# PIC18F46Q24 register map
Vendor: Microchip
Registers are 8-bit, read-write, reset 0x0 unless marked. A register's access mark holds for its fields unless they carry their own. Addresses are absolute, and some are shared; only a register's first bit layout is shown; [hi:lo] are bit positions; {n}, {i} and the like mark numbered series; 'fields as' and 'values as' point back to an identical list.

## tmr
0x312 TMR1L
0x313 TMR1H
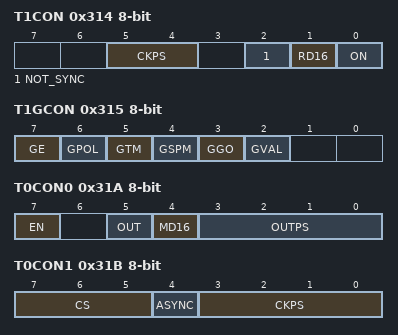
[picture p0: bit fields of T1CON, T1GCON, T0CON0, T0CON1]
0x314 T1CON
  [5:4] CKPS, [2] NOT_SYNC, [1] RD16, [0] ON
0x315 T1GCON reset not defined — (power-on value 00000x--)
  [7] GE, [6] GPOL, [5] GTM, [4] GSPM, [3] GGO, [2] GVAL ro
0x316 T1GATE
  [4:0] GSS
0x317 T1CLK
  [4:0] CS
0x318 TMR0L
0x319 TMR0H reset 0xFF
0x31A T0CON0
  [7] EN, [5] OUT ro, [4] MD16, [3:0] OUTPS
0x31B T0CON1
  [7:5] CS, [4] ASYNC, [3:0] CKPS
0x31D T2TMR — 8-bit period timer
  [7:0] TMR2
0x31E T2PR reset 0xFF
  [7:0] PR2
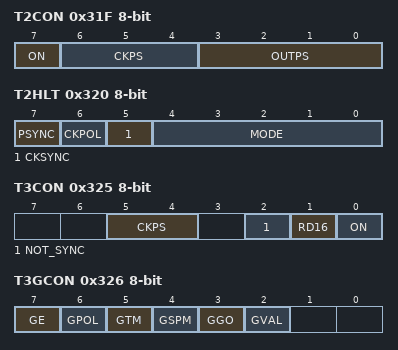
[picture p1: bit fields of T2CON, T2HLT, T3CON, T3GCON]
0x31F T2CON
  [7] ON, [6:4] CKPS, [3:0] OUTPS
0x320 T2HLT
  [7] PSYNC, [6] CKPOL, [5] CKSYNC, [4:0] MODE
0x321 T2CLKCON
  [4:0] CS
0x322 T2RST
  [4:0] RSEL
0x323 TMR3L
0x324 TMR3H
0x325 T3CON
  [5:4] CKPS, [2] NOT_SYNC, [1] RD16, [0] ON
0x326 T3GCON reset not defined — (power-on value 00000x--)
  [7] GE, [6] GPOL, [5] GTM, [4] GSPM, [3] GGO, [2] GVAL ro
0x327 T3GATE
  [4:0] GSS
0x328 T3CLK
  [4:0] CS
0x32A T4TMR — 8-bit period timer
  [7:0] TMR4
0x32B T4PR reset 0xFF
  [7:0] PR4
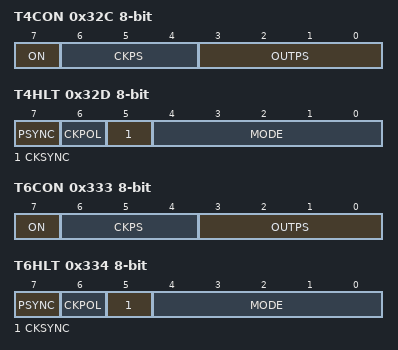
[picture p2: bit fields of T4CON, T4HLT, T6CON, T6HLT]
0x32C T4CON
  [7] ON, [6:4] CKPS, [3:0] OUTPS
0x32D T4HLT
  [7] PSYNC, [6] CKPOL, [5] CKSYNC, [4:0] MODE
0x32E T4CLKCON
  [4:0] CS
0x32F T4RST
  [4:0] RSEL
0x331 T6TMR — 8-bit period timer
  [7:0] TMR6
0x332 T6PR reset 0xFF
  [7:0] PR6
0x333 T6CON
  [7] ON, [6:4] CKPS, [3:0] OUTPS
0x334 T6HLT
  [7] PSYNC, [6] CKPOL, [5] CKSYNC, [4:0] MODE
0x335 T6CLKCON
  [4:0] CS
0x336 T6RST
  [4:0] RSEL
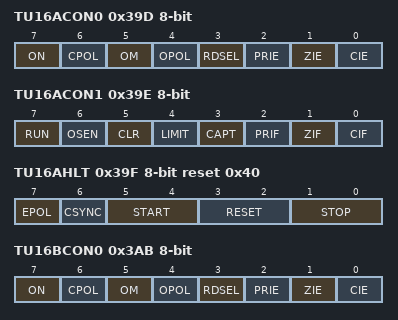
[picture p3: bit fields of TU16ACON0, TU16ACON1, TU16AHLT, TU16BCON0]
0x39D TU16ACON0
  [7] ON, [6] CPOL, [5] OM, [4] OPOL, [3] RDSEL, [2] PRIE, [1] ZIE, [0] CIE
0x39E TU16ACON1
  [7] RUN ro, [6] OSEN, [5] CLR, [4] LIMIT, [3] CAPT, [2] PRIF, [1] ZIF, [0] CIF
0x39F TU16AHLT reset 0x40
  [7] EPOL, [6] CSYNC, [5:4] START, [3:2] RESET, [1:0] STOP
0x3A0 TU16APS
  [7:0] PS
0x3A5 TU16APRL reset 0xFF
  [7:0] PRL
0x3A6 TU16APRH reset 0xFF
  [7:0] PRH
0x3A8 TU16APRT reset 0xFF
  [7:0] PRT
0x3A9 TU16ACLK
  [4:0] CLK
0x3AA TU16AERS
  [5:0] ERS
0x3AB TU16BCON0
  fields as TU16ACON0
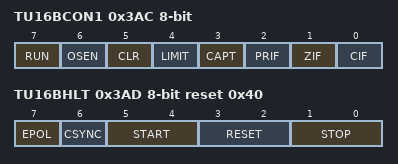
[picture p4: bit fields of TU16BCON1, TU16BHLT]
0x3AC TU16BCON1
  fields as TU16ACON1
0x3AD TU16BHLT reset 0x40
  [7] EPOL, [6] CSYNC, [5:4] START, [3:2] RESET, [1:0] STOP
0x3AE TU16BPS
  [7:0] PS
0x3B3 TU16BPRL reset 0xFF
  [7:0] PRL
0x3B4 TU16BPRH reset 0xFF
  [7:0] PRH
0x3B6 TU16BPRT reset 0xFF
  [7:0] PRT
0x3B7 TU16BCLK
  [4:0] CLK
0x3B8 TU16BERS
  [5:0] ERS

## ccp
0x340 CCPR1L reset not defined — (power-on value xxxxxxxx)
  [7:0] RL
0x341 CCPR1H reset not defined — (power-on value xxxxxxxx)
  [7:0] RH
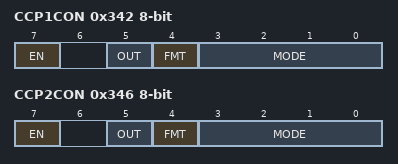
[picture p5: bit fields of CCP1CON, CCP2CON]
0x342 CCP1CON
  [7] EN, [5] OUT ro, [4] FMT, [3:0] MODE
0x343 CCP1CAP
  [3:0] CTS
0x344 CCPR2L reset not defined — (power-on value xxxxxxxx)
  [7:0] RL
0x345 CCPR2H reset not defined — (power-on value xxxxxxxx)
  [7:0] RH
0x346 CCP2CON
  [7] EN, [5] OUT ro, [4] FMT, [3:0] MODE
0x347 CCP2CAP
  [3:0] CTS

## math_progcrc
0x34E CRCDATAL
  [7:0] DATA
0x34F CRCDATAH
  [7:0] DATA
0x350 CRCDATAU
  [7:0] DATA
0x351 CRCDATAT
  [7:0] DATA
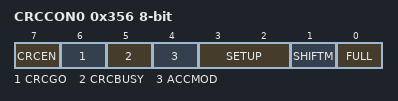
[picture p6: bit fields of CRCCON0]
0x356 CRCCON0
  [7] CRCEN, [6] CRCGO, [5] CRCBUSY ro, [4] ACCMOD, [3:2] SETUP, [1] SHIFTM, [0] FULL ro
0x357 CRCCON1
  [4:0] PLEN
0x358 CRCCON2
  [4:0] DLEN

## nvm_scan
0x35A SCANLADRL
  [7:0] LADR
0x35B SCANLADRH
  [7:0] LADR
0x35C SCANLADRU
  [5:0] LADR
0x35D SCANHADRL reset 0xFF
  [7:0] HADR
0x35E SCANHADRH reset 0xFF
  [7:0] HADR
0x35F SCANHADRU reset 0x3F
  [5:0] HADR
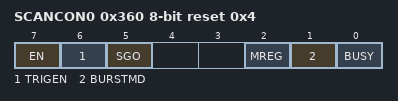
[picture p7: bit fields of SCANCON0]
0x360 SCANCON0 reset 0x4
  [7] EN, [6] TRIGEN, [5] SGO, [2] MREG, [1] BURSTMD, [0] BUSY
0x361 SCANTRIG
  [4:0] TSEL

## wg_ecwg
0x3BC CWG1CLK
  [0] CS
0x3BD CWG1ISM
  [4:0] ISM
0x3BE CWG1DBR
  [5:0] DBR
0x3BF CWG1DBF
  [5:0] DBF
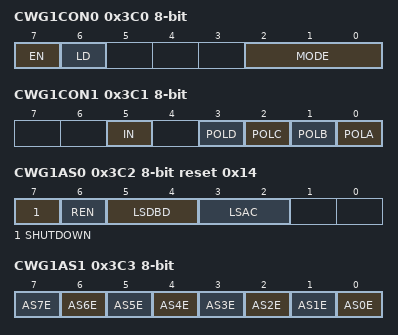
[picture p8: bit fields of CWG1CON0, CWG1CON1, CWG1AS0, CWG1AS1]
0x3C0 CWG1CON0
  [7] EN, [6] LD, [2:0] MODE
0x3C1 CWG1CON1 reset not defined — (power-on value --x-0000)
  [5] IN ro, [3] POLD, [2] POLC, [1] POLB, [0] POLA
0x3C2 CWG1AS0 reset 0x14
  [7] SHUTDOWN, [6] REN, [5:4] LSDBD, [3:2] LSAC
0x3C3 CWG1AS1
  [n] AS{n}E (n=0..7)
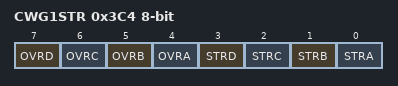
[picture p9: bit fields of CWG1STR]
0x3C4 CWG1STR
  [7] OVRD, [6] OVRC, [5] OVRB, [4] OVRA, [3] STRD, [2] STRC, [1] STRB, [0] STRA
